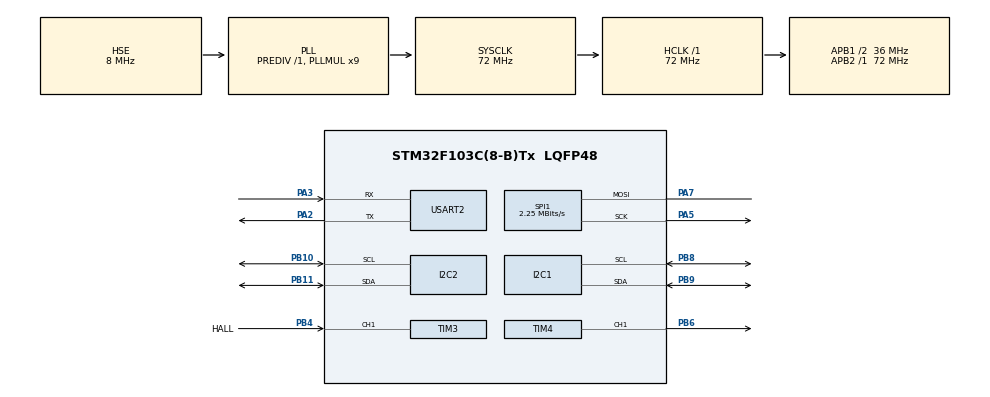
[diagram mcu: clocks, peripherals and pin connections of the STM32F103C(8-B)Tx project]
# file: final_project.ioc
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Dma.Request0=USART2_RX
Dma.Request1=SPI1_TX
Dma.SPI1_TX.1.Direction=DMA_MEMORY_TO_PERIPH
Dma.SPI1_TX.1.Instance=DMA1_Channel3
Dma.SPI1_TX.1.MemDataAlignment=DMA_MDATAALIGN_BYTE
Dma.SPI1_TX.1.MemInc=DMA_MINC_ENABLE
Dma.SPI1_TX.1.Mode=DMA_CIRCULAR
Dma.SPI1_TX.1.PeriphDataAlignment=DMA_PDATAALIGN_BYTE
Dma.SPI1_TX.1.PeriphInc=DMA_PINC_DISABLE
Dma.SPI1_TX.1.Priority=DMA_PRIORITY_VERY_HIGH
Dma.USART2_RX.0.Direction=DMA_PERIPH_TO_MEMORY
Dma.USART2_RX.0.Instance=DMA1_Channel6
Dma.USART2_RX.0.MemDataAlignment=DMA_MDATAALIGN_BYTE
Dma.USART2_RX.0.MemInc=DMA_MINC_ENABLE
Dma.USART2_RX.0.Mode=DMA_NORMAL
Dma.USART2_RX.0.PeriphDataAlignment=DMA_PDATAALIGN_BYTE
Dma.USART2_RX.0.PeriphInc=DMA_PINC_DISABLE
Dma.USART2_RX.0.Priority=DMA_PRIORITY_LOW
I2C2.I2C_Mode=I2C_Standard
Mcu.Family=STM32F1
Mcu.Name=STM32F103C(8-B)Tx
Mcu.Package=LQFP48
NVIC.DMA1_Channel3_IRQn=true\:2\:0\:true\:false\:true\:false\:true\:true
NVIC.DMA1_Channel6_IRQn=true\:1\:0\:true\:false\:true\:false\:true\:true
NVIC.PriorityGroup=NVIC_PRIORITYGROUP_4
NVIC.SPI1_IRQn=true\:0\:0\:false\:false\:true\:true\:true\:true
NVIC.TIM3_IRQn=true\:0\:0\:true\:false\:true\:true\:true\:true
NVIC.USART2_IRQn=true\:0\:0\:false\:false\:true\:true\:true\:true
PA13.Mode=Serial_Wire
PA13.Signal=SYS_JTMS-SWDIO
PA14.Mode=Serial_Wire
PA14.Signal=SYS_JTCK-SWCLK
PA2.Mode=Asynchronous
PA2.Signal=USART2_TX
PA3.Mode=Asynchronous
PA3.Signal=USART2_RX
PA5.Mode=Simplex_Bidirectional_Master
PA5.Signal=SPI1_SCK
PA7.Mode=Simplex_Bidirectional_Master
PA7.Signal=SPI1_MOSI
PB10.Mode=I2C
PB10.Signal=I2C2_SCL
PB11.Mode=I2C
PB11.Signal=I2C2_SDA
PB4.GPIO_Label=HALL
PB4.GPIO_PuPd=GPIO_NOPULL
PB4.Signal=S_TIM3_CH1
PB6.Signal=S_TIM4_CH1
PB8.Mode=I2C
PB8.Signal=I2C1_SCL
PB9.Mode=I2C
PB9.Signal=I2C1_SDA
PD0-OSC_IN.Mode=HSE-External-Oscillator
PD0-OSC_IN.Signal=RCC_OSC_IN
PD1-OSC_OUT.Mode=HSE-External-Oscillator
PD1-OSC_OUT.Signal=RCC_OSC_OUT
ProjectManager.HeapSize=0x200
ProjectManager.StackSize=0x400
ProjectManager.TargetToolchain=STM32CubeIDE
RCC.AHBFreq_Value=72000000
RCC.APB1CLKDivider=RCC_HCLK_DIV2
RCC.APB1Freq_Value=36000000
RCC.APB1TimFreq_Value=72000000
RCC.APB2Freq_Value=72000000
RCC.APB2TimFreq_Value=72000000
RCC.HCLKFreq_Value=72000000
RCC.PLLMUL=RCC_PLL_MUL9
RCC.PLLSourceVirtual=RCC_PLLSOURCE_HSE
RCC.RTCClockSelection=RCC_RTCCLKSOURCE_HSE_DIV128
RCC.SYSCLKFreq_VALUE=72000000
RCC.SYSCLKSource=RCC_SYSCLKSOURCE_PLLCLK
RCC.USBFreq_Value=72000000
SH.S_TIM3_CH1.0=TIM3_CH1,Input_Capture1_from_TI1
SH.S_TIM4_CH1.0=TIM4_CH1,PWM Generation1 CH1
SPI1.BaudRatePrescaler=SPI_BAUDRATEPRESCALER_32
SPI1.CalculateBaudRate=2.25 MBits/s
SPI1.Direction=SPI_DIRECTION_1LINE
SPI1.Mode=SPI_MODE_MASTER
SPI1.VirtualType=VM_MASTER
TIM3.Channel-Input_Capture1_from_TI1=TIM_CHANNEL_1
TIM3.Channel-Output\ Compare2\ No\ Output=TIM_CHANNEL_2
TIM3.ICPolarity_CH1=TIM_INPUTCHANNELPOLARITY_FALLING
TIM3.Period=65535-1
TIM3.Prescaler=7200-1
TIM4.Channel-PWM\ Generation1\ CH1=TIM_CHANNEL_1
TIM4.OCMode_PWM-PWM\ Generation1\ CH1=TIM_OCMODE_PWM2
TIM4.Period=65535 - 1
USART2.VirtualMode=VM_ASYNC
VP_TIM3_VS_ClockSourceINT.Mode=Internal
VP_TIM3_VS_no_output2.Mode=Output Compare2 No Output
VP_TIM4_VS_ClockSourceINT.Mode=Internal
board=custom

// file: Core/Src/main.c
/* USER CODE BEGIN Header */
/**
  ******************************************************************************
  * @file           : main.c
  * @brief          : Main program body
  ******************************************************************************
  * @attention
  *
  * Copyright (c) 2024 STMicroelectronics.
  * All rights reserved.
  *
  * This software is licensed under terms that can be found in the LICENSE file
  * in the root directory of this software component.
  * If no LICENSE file comes with this software, it is provided AS-IS.
  *
  ******************************************************************************
  */
/* USER CODE END Header */
#include "main.h"

/* USER CODE BEGIN Includes */
#include "sys_manage.h"
/* USER CODE END Includes */

I2C_HandleTypeDef hi2c1;
I2C_HandleTypeDef hi2c2;

SPI_HandleTypeDef hspi1;
DMA_HandleTypeDef hdma_spi1_tx;

TIM_HandleTypeDef htim3;
TIM_HandleTypeDef htim4;

UART_HandleTypeDef huart2;
DMA_HandleTypeDef hdma_usart2_rx;

void SystemClock_Config(void);
static void MX_GPIO_Init(void);
static void MX_DMA_Init(void);
static void MX_I2C1_Init(void);
static void MX_USART2_UART_Init(void);
static void MX_TIM4_Init(void);
static void MX_I2C2_Init(void);
static void MX_SPI1_Init(void);
static void MX_TIM3_Init(void);

int main(void)
{

  /* MCU Configuration--------------------------------------------------------*/

  /* Reset of all peripherals, Initializes the Flash interface and the Systick. */
  HAL_Init();

  /* Configure the system clock */
  SystemClock_Config();

  /* Initialize all configured peripherals */
  MX_GPIO_Init();
  MX_DMA_Init();
  MX_I2C1_Init();
  MX_USART2_UART_Init();
  MX_TIM4_Init();
  MX_I2C2_Init();
  MX_SPI1_Init();
  MX_TIM3_Init();
  /* USER CODE BEGIN 2 */
  sys_manage_loop();
  /* USER CODE END 2 */

  /* Infinite loop */
  while (1)
  {

  }
}

void SystemClock_Config(void)
{
  RCC_OscInitTypeDef RCC_OscInitStruct = {0};
  RCC_ClkInitTypeDef RCC_ClkInitStruct = {0};

  /** Initializes the RCC Oscillators according to the specified parameters
  * in the RCC_OscInitTypeDef structure.
  */
  RCC_OscInitStruct.OscillatorType = RCC_OSCILLATORTYPE_HSE;
  RCC_OscInitStruct.HSEState = RCC_HSE_ON;
  RCC_OscInitStruct.HSEPredivValue = RCC_HSE_PREDIV_DIV1;
  RCC_OscInitStruct.HSIState = RCC_HSI_ON;
  RCC_OscInitStruct.PLL.PLLState = RCC_PLL_ON;
  RCC_OscInitStruct.PLL.PLLSource = RCC_PLLSOURCE_HSE;
  RCC_OscInitStruct.PLL.PLLMUL = RCC_PLL_MUL9;
  if (HAL_RCC_OscConfig(&RCC_OscInitStruct) != HAL_OK)
  {
    Error_Handler();
  }

  /** Initializes the CPU, AHB and APB buses clocks
  */
  RCC_ClkInitStruct.ClockType = RCC_CLOCKTYPE_HCLK|RCC_CLOCKTYPE_SYSCLK
                              |RCC_CLOCKTYPE_PCLK1|RCC_CLOCKTYPE_PCLK2;
  RCC_ClkInitStruct.SYSCLKSource = RCC_SYSCLKSOURCE_PLLCLK;
  RCC_ClkInitStruct.AHBCLKDivider = RCC_SYSCLK_DIV1;
  RCC_ClkInitStruct.APB1CLKDivider = RCC_HCLK_DIV2;
  RCC_ClkInitStruct.APB2CLKDivider = RCC_HCLK_DIV1;

  if (HAL_RCC_ClockConfig(&RCC_ClkInitStruct, FLASH_LATENCY_2) != HAL_OK)
  {
    Error_Handler();
  }
}

static void MX_I2C1_Init(void)
{

  hi2c1.Instance = I2C1;
  hi2c1.Init.ClockSpeed = 100000;
  hi2c1.Init.DutyCycle = I2C_DUTYCYCLE_2;
  hi2c1.Init.OwnAddress1 = 0;
  hi2c1.Init.AddressingMode = I2C_ADDRESSINGMODE_7BIT;
  hi2c1.Init.DualAddressMode = I2C_DUALADDRESS_DISABLE;
  hi2c1.Init.OwnAddress2 = 0;
  hi2c1.Init.GeneralCallMode = I2C_GENERALCALL_DISABLE;
  hi2c1.Init.NoStretchMode = I2C_NOSTRETCH_DISABLE;
  if (HAL_I2C_Init(&hi2c1) != HAL_OK)
  {
    Error_Handler();
  }

}

static void MX_I2C2_Init(void)
{

  hi2c2.Instance = I2C2;
  hi2c2.Init.ClockSpeed = 100000;
  hi2c2.Init.DutyCycle = I2C_DUTYCYCLE_2;
  hi2c2.Init.OwnAddress1 = 0;
  hi2c2.Init.AddressingMode = I2C_ADDRESSINGMODE_7BIT;
  hi2c2.Init.DualAddressMode = I2C_DUALADDRESS_DISABLE;
  hi2c2.Init.OwnAddress2 = 0;
  hi2c2.Init.GeneralCallMode = I2C_GENERALCALL_DISABLE;
  hi2c2.Init.NoStretchMode = I2C_NOSTRETCH_DISABLE;
  if (HAL_I2C_Init(&hi2c2) != HAL_OK)
  {
    Error_Handler();
  }

}

static void MX_SPI1_Init(void)
{

  /* SPI1 parameter configuration*/
  hspi1.Instance = SPI1;
  hspi1.Init.Mode = SPI_MODE_MASTER;
  hspi1.Init.Direction = SPI_DIRECTION_1LINE;
  hspi1.Init.DataSize = SPI_DATASIZE_8BIT;
  hspi1.Init.CLKPolarity = SPI_POLARITY_LOW;
  hspi1.Init.CLKPhase = SPI_PHASE_1EDGE;
  hspi1.Init.NSS = SPI_NSS_SOFT;
  hspi1.Init.BaudRatePrescaler = SPI_BAUDRATEPRESCALER_32;
  hspi1.Init.FirstBit = SPI_FIRSTBIT_MSB;
  hspi1.Init.TIMode = SPI_TIMODE_DISABLE;
  hspi1.Init.CRCCalculation = SPI_CRCCALCULATION_DISABLE;
  hspi1.Init.CRCPolynomial = 10;
  if (HAL_SPI_Init(&hspi1) != HAL_OK)
  {
    Error_Handler();
  }

}

static void MX_TIM3_Init(void)
{

  TIM_ClockConfigTypeDef sClockSourceConfig = {0};
  TIM_MasterConfigTypeDef sMasterConfig = {0};
  TIM_IC_InitTypeDef sConfigIC = {0};
  TIM_OC_InitTypeDef sConfigOC = {0};

  htim3.Instance = TIM3;
  htim3.Init.Prescaler = 7200-1;
  htim3.Init.CounterMode = TIM_COUNTERMODE_UP;
  htim3.Init.Period = 65535-1;
  htim3.Init.ClockDivision = TIM_CLOCKDIVISION_DIV1;
  htim3.Init.AutoReloadPreload = TIM_AUTORELOAD_PRELOAD_DISABLE;
  if (HAL_TIM_Base_Init(&htim3) != HAL_OK)
  {
    Error_Handler();
  }
  sClockSourceConfig.ClockSource = TIM_CLOCKSOURCE_INTERNAL;
  if (HAL_TIM_ConfigClockSource(&htim3, &sClockSourceConfig) != HAL_OK)
  {
    Error_Handler();
  }
  if (HAL_TIM_IC_Init(&htim3) != HAL_OK)
  {
    Error_Handler();
  }
  if (HAL_TIM_OC_Init(&htim3) != HAL_OK)
  {
    Error_Handler();
  }
  sMasterConfig.MasterOutputTrigger = TIM_TRGO_RESET;
  sMasterConfig.MasterSlaveMode = TIM_MASTERSLAVEMODE_DISABLE;
  if (HAL_TIMEx_MasterConfigSynchronization(&htim3, &sMasterConfig) != HAL_OK)
  {
    Error_Handler();
  }
  sConfigIC.ICPolarity = TIM_INPUTCHANNELPOLARITY_FALLING;
  sConfigIC.ICSelection = TIM_ICSELECTION_DIRECTTI;
  sConfigIC.ICPrescaler = TIM_ICPSC_DIV1;
  sConfigIC.ICFilter = 0;
  if (HAL_TIM_IC_ConfigChannel(&htim3, &sConfigIC, TIM_CHANNEL_1) != HAL_OK)
  {
    Error_Handler();
  }
  sConfigOC.OCMode = TIM_OCMODE_TIMING;
  sConfigOC.Pulse = 0;
  sConfigOC.OCPolarity = TIM_OCPOLARITY_HIGH;
  sConfigOC.OCFastMode = TIM_OCFAST_DISABLE;
  if (HAL_TIM_OC_ConfigChannel(&htim3, &sConfigOC, TIM_CHANNEL_2) != HAL_OK)
  {
    Error_Handler();
  }

}

static void MX_TIM4_Init(void)
{

  TIM_ClockConfigTypeDef sClockSourceConfig = {0};
  TIM_MasterConfigTypeDef sMasterConfig = {0};
  TIM_OC_InitTypeDef sConfigOC = {0};

  htim4.Instance = TIM4;
  htim4.Init.Prescaler = 0;
  htim4.Init.CounterMode = TIM_COUNTERMODE_UP;
  htim4.Init.Period = 65535 - 1;
  htim4.Init.ClockDivision = TIM_CLOCKDIVISION_DIV1;
  htim4.Init.AutoReloadPreload = TIM_AUTORELOAD_PRELOAD_DISABLE;
  if (HAL_TIM_Base_Init(&htim4) != HAL_OK)
  {
    Error_Handler();
  }
  sClockSourceConfig.ClockSource = TIM_CLOCKSOURCE_INTERNAL;
  if (HAL_TIM_ConfigClockSource(&htim4, &sClockSourceConfig) != HAL_OK)
  {
    Error_Handler();
  }
  if (HAL_TIM_PWM_Init(&htim4) != HAL_OK)
  {
    Error_Handler();
  }
  sMasterConfig.MasterOutputTrigger = TIM_TRGO_RESET;
  sMasterConfig.MasterSlaveMode = TIM_MASTERSLAVEMODE_DISABLE;
  if (HAL_TIMEx_MasterConfigSynchronization(&htim4, &sMasterConfig) != HAL_OK)
  {
    Error_Handler();
  }
  sConfigOC.OCMode = TIM_OCMODE_PWM2;
  sConfigOC.Pulse = 0;
  sConfigOC.OCPolarity = TIM_OCPOLARITY_HIGH;
  sConfigOC.OCFastMode = TIM_OCFAST_DISABLE;
  if (HAL_TIM_PWM_ConfigChannel(&htim4, &sConfigOC, TIM_CHANNEL_1) != HAL_OK)
  {
    Error_Handler();
  }
  HAL_TIM_MspPostInit(&htim4);

}

static void MX_USART2_UART_Init(void)
{

  huart2.Instance = USART2;
  huart2.Init.BaudRate = 115200;
  huart2.Init.WordLength = UART_WORDLENGTH_8B;
  huart2.Init.StopBits = UART_STOPBITS_1;
  huart2.Init.Parity = UART_PARITY_NONE;
  huart2.Init.Mode = UART_MODE_TX_RX;
  huart2.Init.HwFlowCtl = UART_HWCONTROL_NONE;
  huart2.Init.OverSampling = UART_OVERSAMPLING_16;
  if (HAL_UART_Init(&huart2) != HAL_OK)
  {
    Error_Handler();
  }

}

static void MX_DMA_Init(void)
{

  /* DMA controller clock enable */
  __HAL_RCC_DMA1_CLK_ENABLE();

  /* DMA interrupt init */
  /* DMA1_Channel3_IRQn interrupt configuration */
  HAL_NVIC_SetPriority(DMA1_Channel3_IRQn, 2, 0);
  HAL_NVIC_EnableIRQ(DMA1_Channel3_IRQn);
  /* DMA1_Channel6_IRQn interrupt configuration */
  HAL_NVIC_SetPriority(DMA1_Channel6_IRQn, 1, 0);
  HAL_NVIC_EnableIRQ(DMA1_Channel6_IRQn);

}

static void MX_GPIO_Init(void)
{

  /* GPIO Ports Clock Enable */
  __HAL_RCC_GPIOD_CLK_ENABLE();
  __HAL_RCC_GPIOA_CLK_ENABLE();
  __HAL_RCC_GPIOB_CLK_ENABLE();

}

void Error_Handler(void)
{
  __disable_irq();
  while (1)
  {
  }
}
